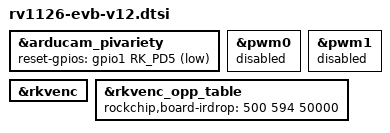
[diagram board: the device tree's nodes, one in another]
// SPDX-License-Identifier: (GPL-2.0+ OR MIT)
/*
 * Copyright (c) 2020 Rockchip Electronics Co., Ltd.
 */

#include "rv1126-evb-v10.dtsi"

&arducam_pivariety {
	reset-gpios = <&gpio1 RK_PD5 GPIO_ACTIVE_LOW>;
};

&pwm0 {
	status = "disabled";
};

&pwm1 {
	status = "disabled";
};

&rkvenc {
	status = "okay";
};

&rkvenc_opp_table {
	/*
	 * max IR-drop values on different freq conditions for this board
	 */
	rockchip,board-irdrop = <
		/* MHz	MHz	uV */
		500	594	50000
	>;
};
